# FM33LC0XX register map
File version: 1.0
CPU: Cortex-M0 r1p0, little endian, no MPU, no FPU, 3 interrupt priority bits
Registers are 32-bit, read-write, reset 0x0 unless marked. A register's access mark holds for its fields unless they carry their own. Offsets are from the block's base; [hi:lo] are bit positions; {n}, {i} and the like mark numbered series.

## DMA — DMA module information
Base 0x40000400
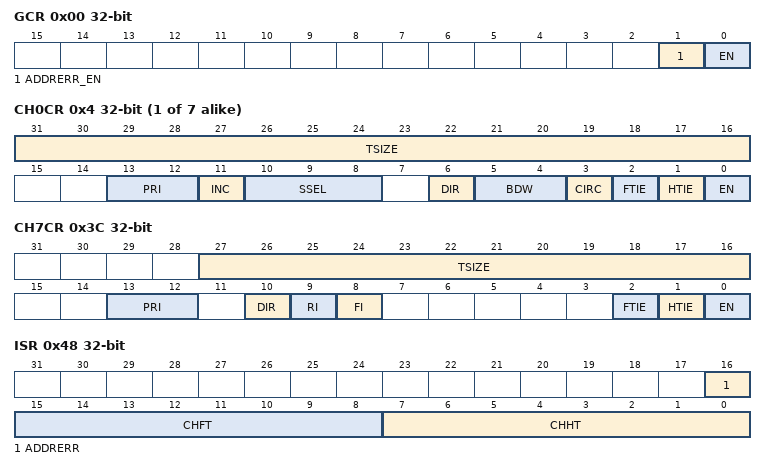
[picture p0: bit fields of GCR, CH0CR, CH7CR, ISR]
0x00 GCR — DMA Global Control Register
  [1] ADDRERR_EN — ADDRERR_EN field description
  [0] EN — EN field description
{0x4+8i} CH{i}CR (i=0..6) — Channel {i} Control Register
  [31:16] TSIZE — TSIZE field description
  [13:12] PRI — PRI field description
  [11] INC — INC field description
  [10:8] SSEL — SSEL field description
  [6] DIR — DIR field description
  [5:4] BDW — BDW field description
  [3] CIRC — CIRC field description
  [2] FTIE — FTIE field description
  [1] HTIE — HTIE field description
  [0] EN — EN field description
{0x8+8i} CH{i}MAD (i=0..6) — Channel {i} Memory Address Register
  [31:0] MEMAD — MEMAD field description
0x3C CH7CR — Channel 7 Control Register
  [27:16] TSIZE — TSIZE field description
  [13:12] PRI — PRI field description
  [10] DIR — DIR field description
  [9] RI — RI field description
  [8] FI — FI field description
  [2] FTIE — FTIE field description
  [1] HTIE — HTIE field description
  [0] EN — EN field description
0x40 CH7FLSAD — Channel 7 Flash Address Register
  [14:0] FLSAD — FLSAD field description
0x44 CH7RAMAD — Channel 7 RAM Address Register
  [11:0] RAMAD — RAMAD field description
0x48 ISR — DMA Interrupt Status Register
  [16] ADDRERR — ADDRERR field description
  [15:8] CHFT — CHFT field description
  [7:0] CHHT — CHHT field description

## CRC — CRC module information
Base 0x40018000
0x00 DR — CRC Data Register
  [31:0] DR — DR field description
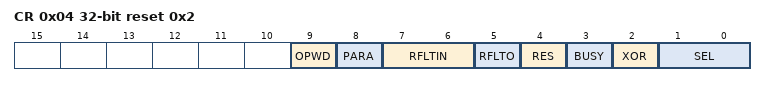
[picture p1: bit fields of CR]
0x04 CR access per field reset 0x2 — CRC Control Register
  [9] OPWD rw — OPWD field description
  [8] PARA rw — PARA field description
  [7:6] RFLTIN rw — RFLTIN field description
  [5] RFLTO rw — RFLTO field description
  [4] RES ro — RES field description
  [3] BUSY ro — BUSY field description
  [2] XOR rw — XOR field description
  [1:0] SEL rw — SEL field description
0x08 LFSR — CRC Linear Feedback Shift Register
  [31:0] LFSR — LFSR field description
0x0C XOR — CRC output XOR Register
  [31:0] XOR — XOR field description
0x1C POLY — CRC Polynominal Register
  [31:0] POLY — POLY field description

## BSTIM — BSTIM module information
Base 0x4001B400
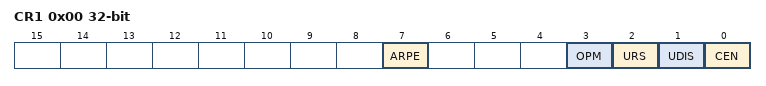
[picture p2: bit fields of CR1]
0x00 CR1 — BSTIM Control Register1
  [7] ARPE — ARPE field description
  [3] OPM — OPM field description
  [2] URS — URS field description
  [1] UDIS — UDIS field description
  [0] CEN — CEN field description
0x04 CR2 — BSTIM Control Register2
  [6:4] MMS — MMS field description
0x0C IER — BSTIM Interrupt Enable Register
  [0] UIE — UIE field description
0x10 ISR — BSTIM Interrupt Status Register
  [0] UIF — UIF field description
0x14 EGR wo — BSTIM Event Generation Register
  [0] UG — UG field description
0x24 CNT — BSTIM Counter Register
  [31:0] CNT — CNT field description
0x28 PSC — BSTIM Prescaler Register
  [31:0] PSC — PSC field description
0x2C ARR — BSTIM Auto-Reload Register
  [31:0] ARR — ARR field description

## LPTIM — LPTIM module information
Base 0x40013400
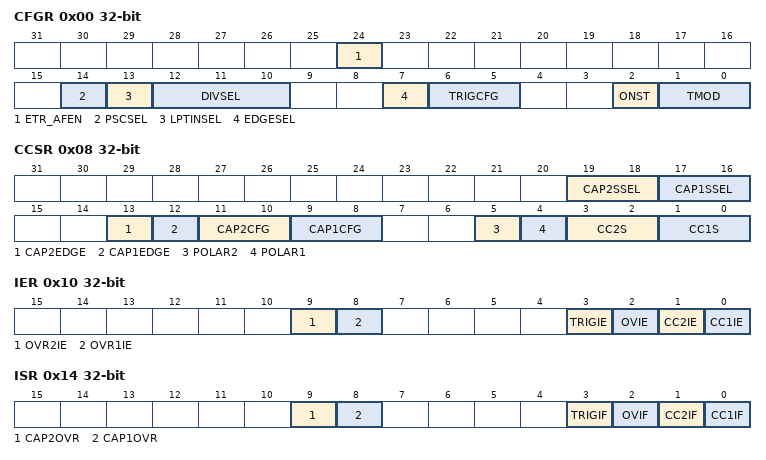
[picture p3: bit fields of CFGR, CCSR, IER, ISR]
0x00 CFGR — LPTIM Config Register
  [24] ETR_AFEN — ETR_AFEN field description
  [14] PSCSEL — PSCSEL field description
  [13] LPTINSEL — LPTINSEL field description
  [12:10] DIVSEL — DIVSEL field description
  [7] EDGESEL — EDGESEL field description
  [6:5] TRIGCFG — TRIGCFG field description
  [2] ONST — ONST field description
  [1:0] TMOD — TMOD field description
0x04 CNT ro — LPTIM Counter Register
  [31:0] CNT32 — CNT32 field description
0x08 CCSR access per field — LPTIM Capture/Compare Control and Status Register
  [19:18] CAP2SSEL rw — CAP2SSEL field description
  [17:16] CAP1SSEL rw — CAP1SSEL field description
  [13] CAP2EDGE ro — CAP2EDGE field description
  [12] CAP1EDGE ro — CAP1EDGE field description
  [11:10] CAP2CFG rw — CAP2CFG field description
  [9:8] CAP1CFG rw — CAP1CFG field description
  [5] POLAR2 rw — POLAR2 field description
  [4] POLAR1 rw — POLAR1 field description
  [3:2] CC2S rw — CC2S field description
  [1:0] CC1S rw — CC1S field description
0x0C ARR — LPTIM Auto-Reload Register
  [31:0] ARR — ARR field description
0x10 IER — LPTIM Interrupt Enable Register
  [9] OVR2IE — OVR2IE field description
  [8] OVR1IE — OVR1IE field description
  [3] TRIGIE — TRIGIE field description
  [2] OVIE — OVIE field description
  [1] CC2IE — CC2IE field description
  [0] CC1IE — CC1IE field description
0x14 ISR — LPTIM Interrupt Status Register
  [9] CAP2OVR — CAP2OVR field description
  [8] CAP1OVR — CAP1OVR field description
  [3] TRIGIF — TRIGIF field description
  [2] OVIF — OVIF field description
  [1] CC2IF — CC2IF field description
  [0] CC1IF — CC1IF field description
0x18 CR — LPTIM Control Register
  [0] EN — EN field description
0x20 CCR1 — LPTIM Capture/Compare Register1
  [31:0] CCR1 — CCR1 field description
0x24 CCR2 — LPTIM Capture/Compare Register2
  [31:0] CCR2 — CCR2 field description
